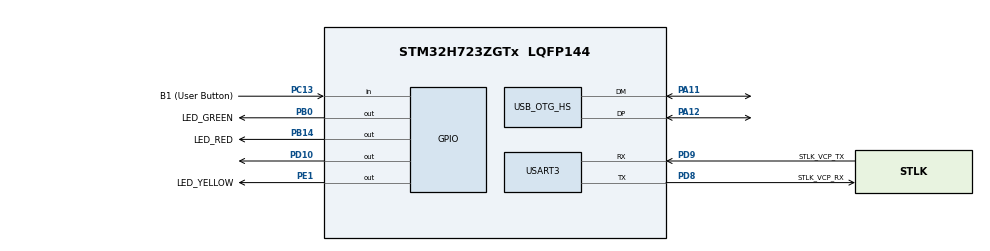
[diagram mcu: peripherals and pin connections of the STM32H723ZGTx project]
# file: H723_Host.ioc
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CORTEX_M7.default_mode_Activation=1
Mcu.Family=STM32H7
Mcu.Name=STM32H723ZGTx
Mcu.Package=LQFP144
NVIC.OTG_HS_IRQn=true\:0\:0\:false\:false\:true\:true\:true\:true
NVIC.PriorityGroup=NVIC_PRIORITYGROUP_4
PA11.Mode=Host_FS
PA11.Signal=USB_OTG_HS_DM
PA12.Mode=Host_FS
PA12.Signal=USB_OTG_HS_DP
PA13(JTMS/SWDIO).GPIO_Label=SWDIO
PA13(JTMS/SWDIO).Signal=DEBUG_JTMS-SWDIO
PA14(JTCK/SWCLK).GPIO_Label=SWCLK
PA14(JTCK/SWCLK).Signal=DEBUG_JTCK-SWCLK
PB0.GPIO_Label=LED_GREEN
PB0.Signal=GPIO_Output
PB14.GPIO_Label=LED_RED
PB14.Signal=GPIO_Output
PC13.GPIO_Label=B1 (User Button)
PC13.Signal=GPIO_Input
PC14-OSC32_IN.Signal=RCC_OSC32_IN
PC15-OSC32_OUT.Signal=RCC_OSC32_OUT
PD10.Signal=GPIO_Output
PD8.GPIO_Label=STLK_VCP_RX
PD8.GPIO_PuPd=GPIO_PULLUP
PD8.GPIO_Speed=GPIO_SPEED_FREQ_VERY_HIGH
PD8.Mode=Asynchronous
PD8.Signal=USART3_TX
PD9.GPIO_Label=STLK_VCP_TX
PD9.GPIO_PuPd=GPIO_PULLUP
PD9.GPIO_Speed=GPIO_SPEED_FREQ_VERY_HIGH
PD9.Mode=Asynchronous
PD9.Signal=USART3_RX
PE1.GPIO_Label=LED_YELLOW
PE1.Signal=GPIO_Output
PH0-OSC_IN.Mode=HSE-External-Oscillator
PH0-OSC_IN.Signal=RCC_OSC_IN
PH1-OSC_OUT.Mode=HSE-External-Oscillator
PH1-OSC_OUT.Signal=RCC_OSC_OUT
ProjectManager.HeapSize=0x200
ProjectManager.StackSize=0x400
ProjectManager.TargetToolchain=STM32CubeIDE
RCC.ADCFreq_Value=76000000
RCC.APB1Freq_Value=130000000
RCC.APB2Freq_Value=130000000
RCC.APB3Freq_Value=130000000
RCC.APB4Freq_Value=130000000
RCC.CortexFreq_Value=520000000
RCC.D1PPRE=RCC_APB3_DIV2
RCC.D2PPRE1=RCC_APB1_DIV2
RCC.D2PPRE2=RCC_APB2_DIV2
RCC.D3PPRE=RCC_APB4_DIV2
RCC.DIVM1=4
RCC.DIVM2=1
RCC.DIVN1=260
RCC.DIVN2=19
RCC.DIVP1=1
RCC.DIVQ1=4
RCC.HCLKFreq_Value=260000000
RCC.HPRE=RCC_HCLK_DIV2
RCC.HSE_VALUE=8000000
RCC.PLLFRACN=0
RCC.PLLSourceVirtual=RCC_PLLSOURCE_HSE
RCC.SYSCLKFreq_VALUE=520000000
RCC.SYSCLKSource=RCC_SYSCLKSOURCE_PLLCLK
RCC.USBCLockSelection=RCC_USBCLKSOURCE_HSI48
RCC.USBFreq_Value=48000000
USART3.VirtualMode-Asynchronous=VM_ASYNC
USB_HOST.BSP.number=1
USB_HOST.USBH_HandleTypeDef=hUsbHostHS
USB_HOST.USBH_MAX_SIZE_CONFIGURATION=256
USB_HOST.VirtualModeHS=Hid
USB_HOST0.BSP.STBoard=false
USB_HOST0.BSP.api=Unknown
USB_HOST0.BSP.condition=SW_VBUS_DRIVE_HID_HS \= false
USB_HOST0.BSP.instance=PD10
USB_HOST0.BSP.ip=GPIO
USB_HOST0.BSP.mode=Output
USB_HOST0.BSP.name=Drive_VBUS_HS
USB_HOST0.BSP.solution=PD10
USB_OTG_HS.VirtualMode-Host_FS=Host_FS
VP_MEMORYMAP_VS_MEMORYMAP.Mode=CurAppReg
VP_RCC_USB.Mode=USB_HS
VP_USB_HOST_VS_USB_HOST_HID_HS.Mode=HID_HS
board=NUCLEO-H723ZG

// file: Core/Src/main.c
/* USER CODE BEGIN Header */
/**
  ******************************************************************************
  * @file           : main.c
  * @brief          : Main program body
  ******************************************************************************
  * @attention
  *
  * Copyright (c) 2025 STMicroelectronics.
  * All rights reserved.
  *
  * This software is licensed under terms that can be found in the LICENSE file
  * in the root directory of this software component.
  * If no LICENSE file comes with this software, it is provided AS-IS.
  *
  ******************************************************************************
  */
/* USER CODE END Header */
#include "main.h"
#include "usb_host.h"

/* USER CODE BEGIN Includes */
#define GETCHAR_PROTOTYPE int __io_getchar(void)
#define PUTCHAR_PROTOTYPE int __io_putchar(int ch)

/* USER CODE END Includes */

UART_HandleTypeDef huart3;

/* USER CODE BEGIN PV */
void UART3_Log(const char *message)
{
    HAL_UART_Transmit(&huart3, (uint8_t*)message, strlen(message), HAL_MAX_DELAY);
}
/* USER CODE END PV */

void SystemClock_Config(void);
static void MPU_Config(void);
static void MX_GPIO_Init(void);
static void MX_USART3_UART_Init(void);
void MX_USB_HOST_Process(void);

/* USER CODE BEGIN PFP */
  #define UART_DISPLAY int fputc(int ch, FILE *f)
/* USER CODE END PFP */

int main(void)
{

  /* MPU Configuration--------------------------------------------------------*/
  MPU_Config();

  /* MCU Configuration--------------------------------------------------------*/

  /* Reset of all peripherals, Initializes the Flash interface and the Systick. */
  HAL_Init();

  /* Configure the system clock */
  SystemClock_Config();

  /* Initialize all configured peripherals */
  MX_GPIO_Init();
  SET_BIT (PWR->CR3, PWR_CR3_USB33DEN);
  MX_USB_HOST_Init();
  MX_USART3_UART_Init();

  /* Infinite loop */
  while (1)
  {
    MX_USB_HOST_Process();

  }
}

void SystemClock_Config(void)
{
  RCC_OscInitTypeDef RCC_OscInitStruct = {0};
  RCC_ClkInitTypeDef RCC_ClkInitStruct = {0};
  RCC_CRSInitTypeDef RCC_CRSInitStruct = {0};

  /** Supply configuration update enable
  */
  HAL_PWREx_ConfigSupply(PWR_LDO_SUPPLY);

  /** Configure the main internal regulator output voltage
  */
  __HAL_PWR_VOLTAGESCALING_CONFIG(PWR_REGULATOR_VOLTAGE_SCALE0);

  while(!__HAL_PWR_GET_FLAG(PWR_FLAG_VOSRDY)) {}

  /** Initializes the RCC Oscillators according to the specified parameters
  * in the RCC_OscInitTypeDef structure.
  */
  RCC_OscInitStruct.OscillatorType = RCC_OSCILLATORTYPE_HSI48|RCC_OSCILLATORTYPE_HSE;
  RCC_OscInitStruct.HSEState = RCC_HSE_ON;
  RCC_OscInitStruct.HSI48State = RCC_HSI48_ON;
  RCC_OscInitStruct.PLL.PLLState = RCC_PLL_ON;
  RCC_OscInitStruct.PLL.PLLSource = RCC_PLLSOURCE_HSE;
  RCC_OscInitStruct.PLL.PLLM = 4;
  RCC_OscInitStruct.PLL.PLLN = 260;
  RCC_OscInitStruct.PLL.PLLP = 1;
  RCC_OscInitStruct.PLL.PLLQ = 4;
  RCC_OscInitStruct.PLL.PLLR = 2;
  RCC_OscInitStruct.PLL.PLLRGE = RCC_PLL1VCIRANGE_1;
  RCC_OscInitStruct.PLL.PLLVCOSEL = RCC_PLL1VCOWIDE;
  RCC_OscInitStruct.PLL.PLLFRACN = 0;
  if (HAL_RCC_OscConfig(&RCC_OscInitStruct) != HAL_OK)
  {
    Error_Handler();
  }

  /** Initializes the CPU, AHB and APB buses clocks
  */
  RCC_ClkInitStruct.ClockType = RCC_CLOCKTYPE_HCLK|RCC_CLOCKTYPE_SYSCLK
                              |RCC_CLOCKTYPE_PCLK1|RCC_CLOCKTYPE_PCLK2
                              |RCC_CLOCKTYPE_D3PCLK1|RCC_CLOCKTYPE_D1PCLK1;
  RCC_ClkInitStruct.SYSCLKSource = RCC_SYSCLKSOURCE_PLLCLK;
  RCC_ClkInitStruct.SYSCLKDivider = RCC_SYSCLK_DIV1;
  RCC_ClkInitStruct.AHBCLKDivider = RCC_HCLK_DIV2;
  RCC_ClkInitStruct.APB3CLKDivider = RCC_APB3_DIV2;
  RCC_ClkInitStruct.APB1CLKDivider = RCC_APB1_DIV2;
  RCC_ClkInitStruct.APB2CLKDivider = RCC_APB2_DIV2;
  RCC_ClkInitStruct.APB4CLKDivider = RCC_APB4_DIV2;

  if (HAL_RCC_ClockConfig(&RCC_ClkInitStruct, FLASH_LATENCY_3) != HAL_OK)
  {
    Error_Handler();
  }

  /** Enable the SYSCFG APB clock
  */
  __HAL_RCC_CRS_CLK_ENABLE();

  /** Configures CRS
  */
  RCC_CRSInitStruct.Prescaler = RCC_CRS_SYNC_DIV1;
  RCC_CRSInitStruct.Source = RCC_CRS_SYNC_SOURCE_USB2;
  RCC_CRSInitStruct.Polarity = RCC_CRS_SYNC_POLARITY_RISING;
  RCC_CRSInitStruct.ReloadValue = __HAL_RCC_CRS_RELOADVALUE_CALCULATE(48000000,1000);
  RCC_CRSInitStruct.ErrorLimitValue = 34;
  RCC_CRSInitStruct.HSI48CalibrationValue = 32;

  HAL_RCCEx_CRSConfig(&RCC_CRSInitStruct);
}

static void MX_USART3_UART_Init(void)
{

  huart3.Instance = USART3;
  huart3.Init.BaudRate = 115200;
  huart3.Init.WordLength = UART_WORDLENGTH_8B;
  huart3.Init.StopBits = UART_STOPBITS_1;
  huart3.Init.Parity = UART_PARITY_NONE;
  huart3.Init.Mode = UART_MODE_TX_RX;
  huart3.Init.HwFlowCtl = UART_HWCONTROL_NONE;
  huart3.Init.OverSampling = UART_OVERSAMPLING_16;
  huart3.Init.OneBitSampling = UART_ONE_BIT_SAMPLE_DISABLE;
  huart3.Init.ClockPrescaler = UART_PRESCALER_DIV1;
  huart3.AdvancedInit.AdvFeatureInit = UART_ADVFEATURE_NO_INIT;
  if (HAL_UART_Init(&huart3) != HAL_OK)
  {
    Error_Handler();
  }
  if (HAL_UARTEx_SetTxFifoThreshold(&huart3, UART_TXFIFO_THRESHOLD_1_8) != HAL_OK)
  {
    Error_Handler();
  }
  if (HAL_UARTEx_SetRxFifoThreshold(&huart3, UART_RXFIFO_THRESHOLD_1_8) != HAL_OK)
  {
    Error_Handler();
  }
  if (HAL_UARTEx_DisableFifoMode(&huart3) != HAL_OK)
  {
    Error_Handler();
  }

}

static void MX_GPIO_Init(void)
{
  GPIO_InitTypeDef GPIO_InitStruct = {0};

  /* GPIO Ports Clock Enable */
  __HAL_RCC_GPIOC_CLK_ENABLE();
  __HAL_RCC_GPIOH_CLK_ENABLE();
  __HAL_RCC_GPIOB_CLK_ENABLE();
  __HAL_RCC_GPIOD_CLK_ENABLE();
  __HAL_RCC_GPIOA_CLK_ENABLE();
  __HAL_RCC_GPIOE_CLK_ENABLE();

  /*Configure GPIO pin Output Level */
  HAL_GPIO_WritePin(GPIOB, LED_GREEN_Pin|LED_RED_Pin, GPIO_PIN_RESET);

  /*Configure GPIO pin Output Level */
  HAL_GPIO_WritePin(GPIOD, GPIO_PIN_10, GPIO_PIN_RESET);

  /*Configure GPIO pin Output Level */
  HAL_GPIO_WritePin(LED_YELLOW_GPIO_Port, LED_YELLOW_Pin, GPIO_PIN_RESET);

  /*Configure GPIO pin : B1_Pin */
  GPIO_InitStruct.Pin = B1_Pin;
  GPIO_InitStruct.Mode = GPIO_MODE_INPUT;
  GPIO_InitStruct.Pull = GPIO_NOPULL;
  HAL_GPIO_Init(B1_GPIO_Port, &GPIO_InitStruct);

  /*Configure GPIO pins : LED_GREEN_Pin LED_RED_Pin */
  GPIO_InitStruct.Pin = LED_GREEN_Pin|LED_RED_Pin;
  GPIO_InitStruct.Mode = GPIO_MODE_OUTPUT_PP;
  GPIO_InitStruct.Pull = GPIO_NOPULL;
  GPIO_InitStruct.Speed = GPIO_SPEED_FREQ_LOW;
  HAL_GPIO_Init(GPIOB, &GPIO_InitStruct);

  /*Configure GPIO pin : PD10 */
  GPIO_InitStruct.Pin = GPIO_PIN_10;
  GPIO_InitStruct.Mode = GPIO_MODE_OUTPUT_PP;
  GPIO_InitStruct.Pull = GPIO_NOPULL;
  GPIO_InitStruct.Speed = GPIO_SPEED_FREQ_LOW;
  HAL_GPIO_Init(GPIOD, &GPIO_InitStruct);

  /*Configure GPIO pin : LED_YELLOW_Pin */
  GPIO_InitStruct.Pin = LED_YELLOW_Pin;
  GPIO_InitStruct.Mode = GPIO_MODE_OUTPUT_PP;
  GPIO_InitStruct.Pull = GPIO_NOPULL;
  GPIO_InitStruct.Speed = GPIO_SPEED_FREQ_LOW;
  HAL_GPIO_Init(LED_YELLOW_GPIO_Port, &GPIO_InitStruct);

}

 /* MPU Configuration */

void MPU_Config(void)
{
  MPU_Region_InitTypeDef MPU_InitStruct = {0};

  /* Disables the MPU */
  HAL_MPU_Disable();

  /** Initializes and configures the Region and the memory to be protected
  */
  MPU_InitStruct.Enable = MPU_REGION_ENABLE;
  MPU_InitStruct.Number = MPU_REGION_NUMBER0;
  MPU_InitStruct.BaseAddress = 0x0;
  MPU_InitStruct.Size = MPU_REGION_SIZE_4GB;
  MPU_InitStruct.SubRegionDisable = 0x87;
  MPU_InitStruct.TypeExtField = MPU_TEX_LEVEL0;
  MPU_InitStruct.AccessPermission = MPU_REGION_NO_ACCESS;
  MPU_InitStruct.DisableExec = MPU_INSTRUCTION_ACCESS_DISABLE;
  MPU_InitStruct.IsShareable = MPU_ACCESS_SHAREABLE;
  MPU_InitStruct.IsCacheable = MPU_ACCESS_NOT_CACHEABLE;
  MPU_InitStruct.IsBufferable = MPU_ACCESS_NOT_BUFFERABLE;

  HAL_MPU_ConfigRegion(&MPU_InitStruct);
  /* Enables the MPU */
  HAL_MPU_Enable(MPU_PRIVILEGED_DEFAULT);

}

void Error_Handler(void)
{
  __disable_irq();
  while (1)
  {
  }
}
